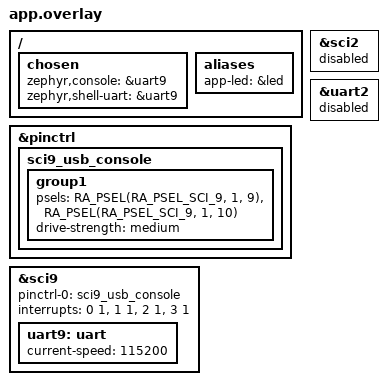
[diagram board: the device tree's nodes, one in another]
/*
 * DeviceTree overlay for Arduino UNO R4 WiFi.
 * Routes the Zephyr console to UART9 (connected to the ESP32-S3 USB-to-serial bridge).
 */
/ {
	chosen {
		zephyr,console = &uart9;
		zephyr,shell-uart = &uart9;
	};
};

&pinctrl {
	sci9_usb_console: sci9_usb_console {
		group1 {
			/* UART connected to the UNO R4 WiFi ESP32-S3 USB bridge. */
			psels = <RA_PSEL(RA_PSEL_SCI_9, 1, 9)>,
				<RA_PSEL(RA_PSEL_SCI_9, 1, 10)>;
			drive-strength = "medium";
		};
	};
};

&sci2 {
	status = "disabled";
};

&uart2 {
	status = "disabled";
};

&sci9 {
	pinctrl-0 = <&sci9_usb_console>;
	pinctrl-names = "default";
	interrupts = <0 1>, <1 1>, <2 1>, <3 1>;
	interrupt-names = "rxi", "txi", "tei", "eri";
	status = "okay";

	uart9: uart {
		current-speed = <115200>;
		status = "okay";
	};
};

/ {
	aliases {
		app-led = &led;
	};
};
